# ESP32-H4 register map
Vendor: ESPRESSIF SYSTEMS (SHANGHAI) CO., LTD.; Series: ESP32 H-Series; File version: 1
CPU: RV32IMAC r0p0, little endian, no MPU, no FPU, 0 interrupt priority bits
Address unit: 32 bits
Registers are 32-bit, read-write, reset 0x0 unless marked. A register's access mark holds for its fields unless they carry their own. Offsets are from the block's base; [hi:lo] are bit positions; {n}, {i} and the like mark numbered series; 'fields as' and 'values as' point back to an identical list.

## CPU_APM — CPU_APM Peripheral
Base 0x6009E000
0x00 REGION_FILTER_EN reset 0x1 — Region filter enable register
  [7:0] REGION_FILTER_EN — Configure bit 0 (0-7) to enable region 0.\\ 0: disable \\ 1: enable \\
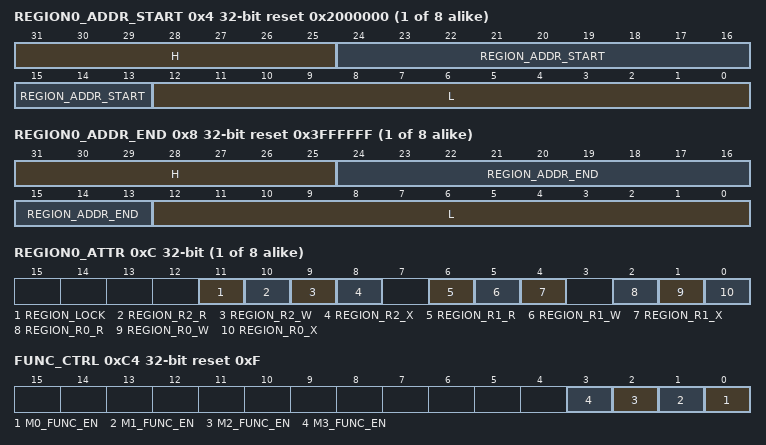
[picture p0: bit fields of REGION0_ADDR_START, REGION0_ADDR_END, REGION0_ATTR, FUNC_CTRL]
{0x4+0xC*i} REGION{i}_ADDR_START (i=0..7) access per field reset 0x2000000 — Region address register
  [31:25] H ro — High 13 bit, start address of region %s.
  [24:13] REGION_ADDR_START rw — Configures start address of region %s.
  [12:0] L ro — Low 12 bit, start address of region %s.
{0x8+0xC*i} REGION{i}_ADDR_END (i=0..7) access per field reset 0x3FFFFFF — Region address register
  [31:25] H ro — High 13 bit, end address of region %s.
  [24:13] REGION_ADDR_END rw — Configures end address of region %s.
  [12:0] L ro — Low 12 bit, end address of region %s.
{0xC+0xC*i} REGION{i}_ATTR (i=0..7) — Region access authority attribute register
  [11] REGION_LOCK — Set 1 to lock region0 configuration
  [10] REGION_R2_R — Configures the read authority of REE_MODE 2 in region %s.
  [9] REGION_R2_W — Configures the write authority of REE_MODE 2 in region %s.
  [8] REGION_R2_X — Configures the execution authority of REE_MODE 2 in region %s.
  [6] REGION_R1_R — Configures the read authority of REE_MODE 1 in region %s.
  [5] REGION_R1_W — Configures the write authority of REE_MODE 1 in region %s.
  [4] REGION_R1_X — Configures the execution authority of REE_MODE 1 in region %s.
  [2] REGION_R0_R — Configures the read authority of REE_MODE 0 in region %s.
  [1] REGION_R0_W — Configures the write authority of REE_MODE 0 in region %s.
  [0] REGION_R0_X — Configures the execution authority of REE_MODE 0 in region %s.
0xC4 FUNC_CTRL reset 0xF — APM function control register
  [n] M{n}_FUNC_EN (n=0..3) — PMS M{n} function enable
{0xC8+0x10*i} M{i}_STATUS ro (i=0..3)
  [1:0] M{i}_EXCEPTION_STATUS — Represents exception status.\\ bit0: 1 represents authority_exception \\ bit1: 1 represents space_exception \\
{0xCC+0x10*i} M{i}_STATUS_CLR wo (i=0..3) — M{i} status clear register
  [0] M{i}_EXCEPTION_STATUS_CLR — Configures to clear exception status.
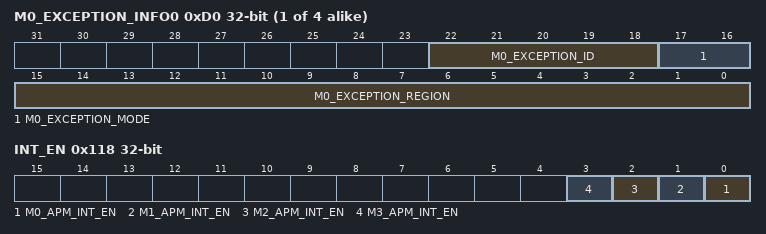
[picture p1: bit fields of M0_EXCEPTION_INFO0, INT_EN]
{0xD0+0x10*i} M{i}_EXCEPTION_INFO0 ro (i=0..3)
  [22:18] M{i}_EXCEPTION_ID — Represents exception id information.
  [17:16] M{i}_EXCEPTION_MODE — Represents exception mode.
  [15:0] M{i}_EXCEPTION_REGION — Represents exception region.
{0xD4+0x10*i} M{i}_EXCEPTION_INFO1 ro (i=0..3)
  [31:0] M{i}_EXCEPTION_ADDR — Represents exception addr.
0x118 INT_EN — APM interrupt enable register
  [n] M{n}_APM_INT_EN (n=0..3) — Configures to enable APM M{n} interrupt.\\ 0: disable \\ 1: enable \\
0x7F8 CLOCK_GATE reset 0x1 — Clock gating register
  [0] CLK_EN — Configures whether to keep the clock always on.\\ 0: enable automatic clock gating \\ 1: keep the clock always on \\
0x7FC DATE reset 0x2504220 — Version control register
  [27:0] DATE — Version control register.

## HP_APM — HP_APM Peripheral
Base 0x6009D000
Registers as CPU_APM, without REGION*_ADDR_START, REGION*_ADDR_END, REGION*_ATTR; these are added or differ:
0x00 REGION_FILTER_EN reset 0x1 — Region filter enable register
  [15:0] REGION_FILTER_EN — Configure bit 0 (0-15) to enable region 0.\\ 0: disable \\ 1: enable \\
{0x4+0xC*i} REGION{i}_ADDR_START (i=0..15) — Region address register
  [31:0] REGION_ADDR_START — Configures start address of region %s.
{0x8+0xC*i} REGION{i}_ADDR_END (i=0..15) reset 0xFFFFFFFF — Region address register
  [31:0] REGION_ADDR_END — Configures end address of region %s.
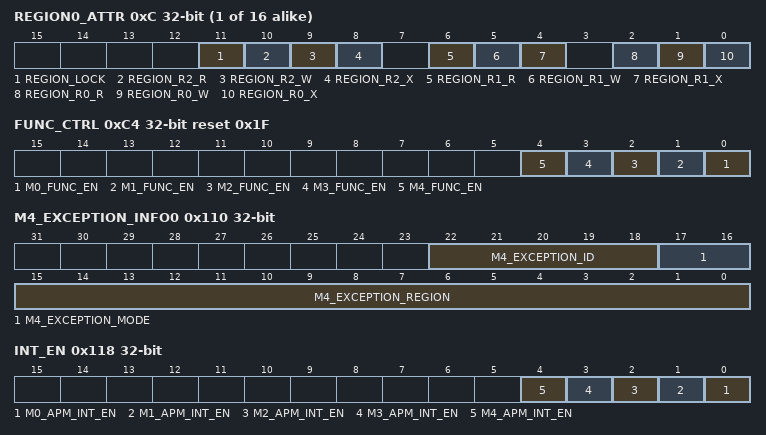
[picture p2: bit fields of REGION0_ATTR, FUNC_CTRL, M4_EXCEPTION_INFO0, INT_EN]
{0xC+0xC*i} REGION{i}_ATTR (i=0..15) — Region access authority attribute register
  fields as CPU_APM.REGION0_ATTR
0xC4 FUNC_CTRL reset 0x1F — APM function control register
  [n] M{n}_FUNC_EN (n=0..4) — PMS M{n} function enable
0x108 M4_STATUS ro
  [1:0] M4_EXCEPTION_STATUS — Represents exception status.\\ bit0: 1 represents authority_exception \\ bit1: 1 represents space_exception \\
0x10C M4_STATUS_CLR wo — M4 status clear register
  [0] M4_EXCEPTION_STATUS_CLR — Configures to clear exception status.
0x110 M4_EXCEPTION_INFO0 ro
  [22:18] M4_EXCEPTION_ID — Represents exception id information.
  [17:16] M4_EXCEPTION_MODE — Represents exception mode.
  [15:0] M4_EXCEPTION_REGION — Represents exception region.
0x114 M4_EXCEPTION_INFO1 ro
  [31:0] M4_EXCEPTION_ADDR — Represents exception addr.
0x118 INT_EN — APM interrupt enable register
  [n] M{n}_APM_INT_EN (n=0..4) — Configures to enable APM M{n} interrupt.\\ 0: disable \\ 1: enable \\
0x7FC DATE reset 0x2312010 — Version control register
  [27:0] DATE — Version control register.
